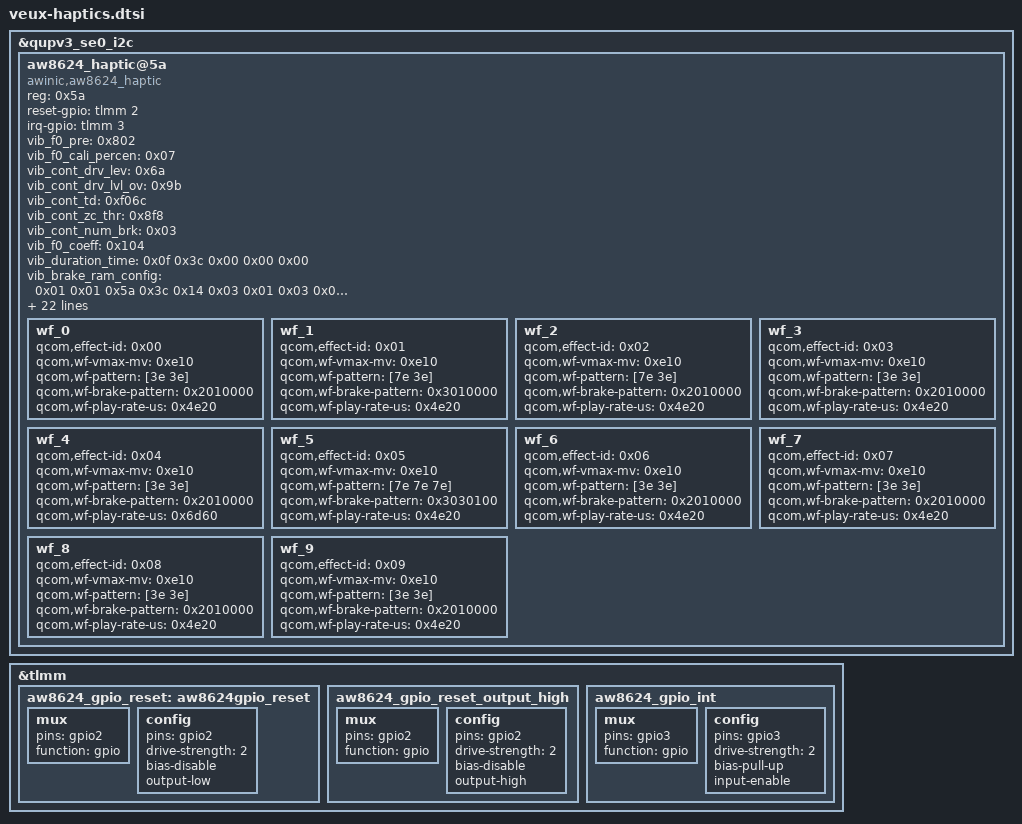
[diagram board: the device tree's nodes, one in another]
&qupv3_se0_i2c {
	aw8624_haptic@5a {
		compatible = "awinic,aw8624_haptic";
		reg = <0x5a>;
		reset-gpio = <&tlmm 2 GPIO_ACTIVE_HIGH>;
		irq-gpio = <&tlmm 3 GPIO_ACTIVE_HIGH>;
		vib_f0_pre = <0x802>;
		vib_f0_cali_percen = <0x07>;
		vib_cont_drv_lev = <0x6a>;
		vib_cont_drv_lvl_ov = <0x9b>;
		vib_cont_td = <0xf06c>;
		vib_cont_zc_thr = <0x8f8>;
		vib_cont_num_brk = <0x03>;
		vib_f0_coeff = <0x104>;
		vib_duration_time = <0x0f 0x3c 0x00 0x00 0x00>;
		vib_brake_ram_config = <0x01 0x01 0x5a 0x3c 0x14 0x03 0x01 0x03 0x01 0x01 0x5a 0x3c 0x1e 0x05 0x01 0x03 0x00 0x00 0x32 0x28 0x19 0x00 0x05 0x03>;
		vib_brake_cont_config = <0x01 0x01 0x5a 0x2a 0x14 0x05 0x02 0x02 0x00 0x00 0x00 0x00 0x00 0x00 0x00 0x00 0x00 0x00 0x00 0x00 0x00 0x00 0x00 0x00>;
		vib_f0_trace_parameter = <0x09 0x05 0x01 0x0f>;
		vib_bemf_config = <0x00 0x08 0x03 0xf8>;
		vib_sw_brake = <0x2c>;
		vib_wavseq = <0x00 0x01 0x01 0x02 0x00 0x00 0x00 0x00 0x00 0x00 0x00 0x00 0x00 0x00 0x00 0x00>;
		vib_wavloop = <0x00 0x06 0x01 0x0f 0x00 0x00 0x00 0x00 0x00 0x00>;
		vib_td_brake = <0xa6e0 0xa6e0 0xa6e0>;
		vib_tset = <0x11>;
		vib_func_parameter1 = <0x01>;
		vib_gain_flag = <0x01>;
		vib_r_spare = <0x68>;
		vib_bstdbg = <0x30 0xeb 0xd4 0x00 0x00 0x00>;
		vib_effect_id_boundary = <0x0a>;
		vib_effect_max = <0x209>;
		vib_rtp_time = <0x14 0x14 0x14 0x14 0x14 0x14 0x14 0x14 0x14 0x1e 0x28 0x32 0x3c 0x46 0x50 0x5a 0x64 0x6e 0x78 0x82 0x8c 0x96 0xa0 0xaa 0xb4 0xbe 0xc8 0xd2 0xdc 0xe6 0xf0 0xfa 0x104 0x10e 0x118 0x122 0x12c 0x136 0x140 0x14a 0x14 0x14 0x14 0x14 0x14 0x14 0x14 0x14 0x14 0x14 0x14 0x14 0x14 0x14 0x14 0x14 0x14 0x14 0x14 0x14 0x14 0x14 0x14 0x14 0x14 0x14 0x14 0x14 0x14 0x14 0x14 0x14 0x14 0x14 0x14 0x14 0x14 0x14 0x14 0x14 0x14 0x14 0x14 0x14 0x14 0x14 0x14 0x14 0x14 0x14 0x14 0x14 0x14 0x14 0x14 0x14 0x14 0x14 0x14 0x14 0x14 0x14 0x14 0x14 0x14 0x14 0x14 0x14 0x14 0x14 0x14 0x14 0x14 0x14 0x14 0x14 0x14 0x14 0x14 0x14 0x14 0x14 0x14 0x14 0x14 0x14 0x14 0x14 0x14 0x14 0x14 0x14 0x14 0x14 0x14 0x14 0x14 0x14 0x14 0x14 0x14 0x14 0x14 0x14 0x14 0x14 0x14 0x14 0x14 0x14 0x14 0x14 0x14 0x14 0x14 0x14 0x14 0x14 0x14 0x14 0x14 0x14 0x14 0x14 0x14 0x14 0x14 0x14 0x14 0x14 0x14 0x14 0x14 0x14 0x14>;
		pinctrl-names = "aw8624_reset_reset",
			"aw8624_reset_active",
			"aw8624_interrupt_active";
		pinctrl-0 = <&aw8624_gpio_reset>;
		pinctrl-1 = <&aw8624_gpio_reset_output_high>;
		pinctrl-2 = <&aw8624_gpio_int>;

		wf_0 {
			qcom,effect-id = <0x00>;
			qcom,wf-vmax-mv = <0xe10>;
			qcom,wf-pattern = [3e 3e];
			qcom,wf-brake-pattern = <0x2010000>;
			qcom,wf-play-rate-us = <0x4e20>;
		};

		wf_1 {
			qcom,effect-id = <0x01>;
			qcom,wf-vmax-mv = <0xe10>;
			qcom,wf-pattern = [7e 3e];
			qcom,wf-brake-pattern = <0x3010000>;
			qcom,wf-play-rate-us = <0x4e20>;
		};

		wf_2 {
			qcom,effect-id = <0x02>;
			qcom,wf-vmax-mv = <0xe10>;
			qcom,wf-pattern = [7e 3e];
			qcom,wf-brake-pattern = <0x2010000>;
			qcom,wf-play-rate-us = <0x4e20>;
		};

		wf_3 {
			qcom,effect-id = <0x03>;
			qcom,wf-vmax-mv = <0xe10>;
			qcom,wf-pattern = [3e 3e];
			qcom,wf-brake-pattern = <0x2010000>;
			qcom,wf-play-rate-us = <0x4e20>;
		};

		wf_4 {
			qcom,effect-id = <0x04>;
			qcom,wf-vmax-mv = <0xe10>;
			qcom,wf-pattern = [3e 3e];
			qcom,wf-brake-pattern = <0x2010000>;
			qcom,wf-play-rate-us = <0x6d60>;
		};

		wf_5 {
			qcom,effect-id = <0x05>;
			qcom,wf-vmax-mv = <0xe10>;
			qcom,wf-pattern = [7e 7e 7e];
			qcom,wf-brake-pattern = <0x3030100>;
			qcom,wf-play-rate-us = <0x4e20>;
		};

		wf_6 {
			qcom,effect-id = <0x06>;
			qcom,wf-vmax-mv = <0xe10>;
			qcom,wf-pattern = [3e 3e];
			qcom,wf-brake-pattern = <0x2010000>;
			qcom,wf-play-rate-us = <0x4e20>;
		};

		wf_7 {
			qcom,effect-id = <0x07>;
			qcom,wf-vmax-mv = <0xe10>;
			qcom,wf-pattern = [3e 3e];
			qcom,wf-brake-pattern = <0x2010000>;
			qcom,wf-play-rate-us = <0x4e20>;
		};

		wf_8 {
			qcom,effect-id = <0x08>;
			qcom,wf-vmax-mv = <0xe10>;
			qcom,wf-pattern = [3e 3e];
			qcom,wf-brake-pattern = <0x2010000>;
			qcom,wf-play-rate-us = <0x4e20>;
		};

		wf_9 {
			qcom,effect-id = <0x09>;
			qcom,wf-vmax-mv = <0xe10>;
			qcom,wf-pattern = [3e 3e];
			qcom,wf-brake-pattern = <0x2010000>;
			qcom,wf-play-rate-us = <0x4e20>;
		};
	};
};

&tlmm {
	aw8624_gpio_reset: aw8624gpio_reset {
		mux {
			pins = "gpio2";
			function = "gpio";
		};

		config {
			pins = "gpio2";
			drive-strength = <2>;
			bias-disable;
			output-low;
		};
	};

	aw8624_gpio_reset_output_high: aw8624_gpio_reset_output_high {
		mux {
			pins = "gpio2";
			function = "gpio";
		};

		config {
			pins = "gpio2";
			drive-strength = <2>;
			bias-disable;
			output-high;
		};
	};

	aw8624_gpio_int: aw8624_gpio_int {
		mux {
			pins = "gpio3";
			function = "gpio";
		};

		config {
			pins = "gpio3";
			drive-strength = <2>;
			bias-pull-up;
			input-enable;
		};
	};
};
